# GD32C231 register map
File version: 1.0
CPU: CM23 r0p0, little endian, MPU, FPU, 4 interrupt priority bits
Registers are 32-bit, read-write, reset 0x0 unless marked. A register's access mark holds for its fields unless they carry their own. Offsets are from the block's base; [hi:lo] are bit positions; {n}, {i} and the like mark numbered series.

## TIMER2 — General-level0-timers
Base 0x40000400
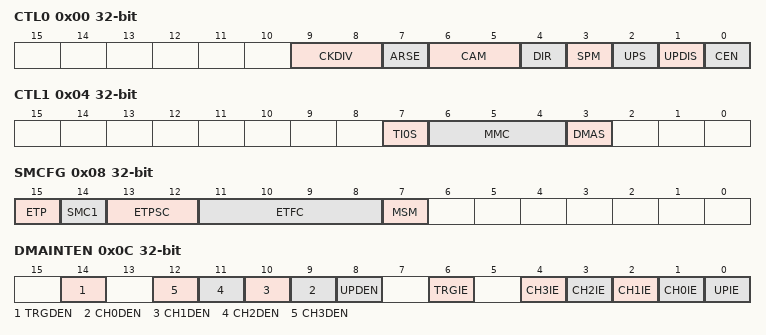
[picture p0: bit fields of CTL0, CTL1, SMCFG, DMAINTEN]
0x00 CTL0 — control register 0
  [9:8] CKDIV — Clock division
  [7] ARSE — Auto-reload shadow enable
  [6:5] CAM — Counter aligns mode selection
  [4] DIR — Direction
  [3] SPM — Single pulse mode
  [2] UPS — Update request source
  [1] UPDIS — Update disable
  [0] CEN — Counter enable
0x04 CTL1 — control register 1
  [7] TI0S — Channel 0 trigger input selection
  [6:4] MMC — Master mode control
  [3] DMAS — DMA request source selection
0x08 SMCFG — Slave mode configuration register
  [15] ETP — External trigger polarity
  [14] SMC1 — Part of SMC for enable External clock mode1
  [13:12] ETPSC — External trigger prescaler
  [11:8] ETFC — External trigger filter control
  [7] MSM — Master/Slave mode
0x0C DMAINTEN — DMA and interrupt enable register
  [14] TRGDEN — Trigger DMA request enable
  [n+9] CH{n}DEN (n=0..3) — Channel {n} Capture/Compare DMA request enable
  [8] UPDEN — Update DMA request enable
  [6] TRGIE — Trigger interrupt enable
  [n+1] CH{n}IE (n=0..3) — Channel {n} Capture/Compare interrupt enable
  [0] UPIE — Update Capture/Compare interrupt enable
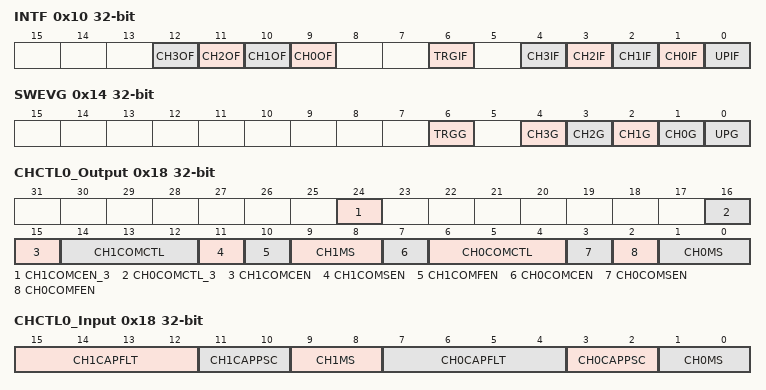
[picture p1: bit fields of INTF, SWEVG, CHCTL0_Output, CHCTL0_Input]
0x10 INTF — interrupt flag register
  [n+9] CH{n}OF (n=0..3) — Channel {n} Capture overflow flag
  [6] TRGIF — Trigger interrupt flag
  [4] CH3IF — Channel 3 Capture/Compare interrupt enable
  [3] CH2IF — Channel 2 Capture/Compare interrupt enable
  [2] CH1IF — Channel 1 Capture/Compare interrupt enable
  [1] CH0IF — Channel 0 Capture/Compare interrupt flag
  [0] UPIF — Update interrupt flag
0x14 SWEVG wo — event generation register
  [6] TRGG — Trigger generation
  [n+1] CH{n}G (n=0..3) — Channel {n} capture or compare event generation
  [0] UPG — Update generation
0x18 CHCTL0_Output — Channel control register 0 (output mode)
  [24] CH1COMCEN_3 — Channel 1 compare output control
  [16] CH0COMCTL_3 — Channel 0 compare output control
  [15] CH1COMCEN — Channel 1 output compare clear enable
  [14:12] CH1COMCTL — Channel 1 output compare mode
  [11] CH1COMSEN — Channel 1 output compare shadow enable
  [10] CH1COMFEN — Channel 1 output compare fast enable
  [9:8] CH1MS — Channel 1 mode selection
  [7] CH0COMCEN — Channel 0 output compare clear enable
  [6:4] CH0COMCTL — Channel 0 compare output control
  [3] CH0COMSEN — Channel 0 output compare shadow enable
  [2] CH0COMFEN — Channel 0 output compare fast enable
  [1:0] CH0MS — Channel 0 mode selection
0x18 CHCTL0_Input (alternate view of CHCTL0_Output) — Channel control register 0 (input mode)
  [15:12] CH1CAPFLT — Channel 1 input capture filter control
  [11:10] CH1CAPPSC — Channel 1 input capture prescaler
  [9:8] CH1MS — Channel 1 mode selection
  [7:4] CH0CAPFLT — Channel 0 input capture filter control
  [3:2] CH0CAPPSC — Channel 0 input capture prescaler
  [1:0] CH0MS — Channel 0 mode selection
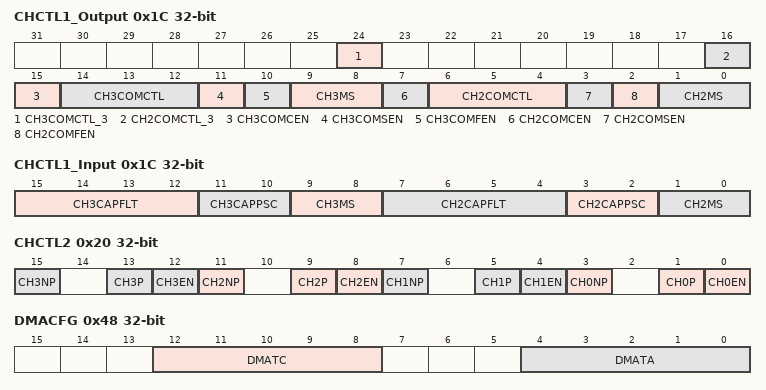
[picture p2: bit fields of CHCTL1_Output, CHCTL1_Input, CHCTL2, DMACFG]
0x1C CHCTL1_Output — Channel control register 1 (output mode)
  [24] CH3COMCTL_3 — Channel 3 compare output control
  [16] CH2COMCTL_3 — Channel 2 compare output control
  [15] CH3COMCEN — Channel 3 output compare clear enable
  [14:12] CH3COMCTL — Channel 3 compare output control
  [11] CH3COMSEN — Channel 3 compare output control
  [10] CH3COMFEN — Channel 3 output compare fast enable
  [9:8] CH3MS — Channel 3 mode selection
  [7] CH2COMCEN — Channel 2 output compare clear enable
  [6:4] CH2COMCTL — Channel 2 compare output control
  [3] CH2COMSEN — Channel 2 output compare shadow enable
  [2] CH2COMFEN — Channel 2 output compare fast enable
  [1:0] CH2MS — Channel 2 mode selection
0x1C CHCTL1_Input (alternate view of CHCTL1_Output) — Channel control register 1 (input mode)
  [15:12] CH3CAPFLT — Channel 3 input capture filter control
  [11:10] CH3CAPPSC — Channel 3 input capture prescaler
  [9:8] CH3MS — Channel 3 mode selection
  [7:4] CH2CAPFLT — Channel 2 input capture filter control
  [3:2] CH2CAPPSC — Channel 2 input capture prescaler
  [1:0] CH2MS — Channel 2 mode selection
0x20 CHCTL2 — Channel control register 2
  [4n+3] CH{n}NP (n=0..3) — Channel {n} complementary output polarity
  [4n+1] CH{n}P (n=0..3) — Channel {n} polarity
  [4n] CH{n}EN (n=0..3) — Channel {n} enable
0x24 CNT — Counter register
  [15:0] CNT — current counter value
0x28 PSC — Prescaler register
  [15:0] PSC — Prescaler value of the counter clock
0x2C CAR — Counter auto reload register
  [15:0] CAR — Low Auto-reload value
0x34 CH0CV — Channel 0 capture/compare value register
  [15:0] CH0VAL — Capture or compare value of channel 0
0x38 CH1CV — Channel 1 capture/compare value register
  [15:0] CH1VAL — Capture or compare value of channel 1
0x3C CH2CV — Channel 2 capture/compare value registerV
  [15:0] CH2VAL — Capture or compare value of channel 2
0x40 CH3CV — Channel 3 capture/compare value register
  [15:0] CH3VAL — Capture or compare value of channel 3
0x48 DMACFG — DMA configuration register
  [12:8] DMATC — DMA transfer count
  [4:0] DMATA — DMA transfer access start address
0x4C DMATB — DMA Transfer buffer register
  [15:0] DMATB — DMA transfer
0xFC CFG — Configuration register
  [1] CHVSEL — Write CHxVAL register selection
